# RT58X register map
Series: ARMv8-M Mainline; File version: 1.0
CPU: CM3 r0p0, little endian, MPU, no FPU, VTOR, 3 interrupt priority bits
Registers are 32-bit, read-write, reset 0x0 unless marked. A register's access mark holds for its fields unless they carry their own. Offsets are from the block's base; [hi:lo] are bit positions.

## CACHECTRL — CACHECTRL Register block
Base 0xA0200000
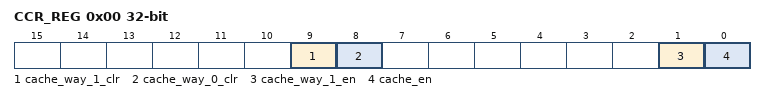
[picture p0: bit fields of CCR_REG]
0x00 CCR_REG — ccr
  [9] cache_way_1_clr wo — clear way 1 cache
    0=B_9 (clear way 1 cache)
  [8] cache_way_0_clr wo — clear way 0 cache
    0=B_8 (clear way 0 cache)
  [1] cache_way_1_en — 0: Cache 1 way (way 1 disable) 1: Cache 2 way (way 1 enable)
    0=B_1 (0: Cache 1 way (way 1 disable) 1: Cache 2 way (way 1 enable))
  [0] cache_en — 0: Cache Disable 1: Cache Enable
    0=B_0 (0: Cache Disable 1: Cache Enable)

## UART1 — UART1 Register block
Base 0xA0500000
0x00 UART1_THR_RBR_REG — uart1 thr rbr
  [7:0] THR_RBR — For write, data to be transmitted. For read, received data.
    0=B_0_to_7 (For write, data to be transmitted. For read, received data.)
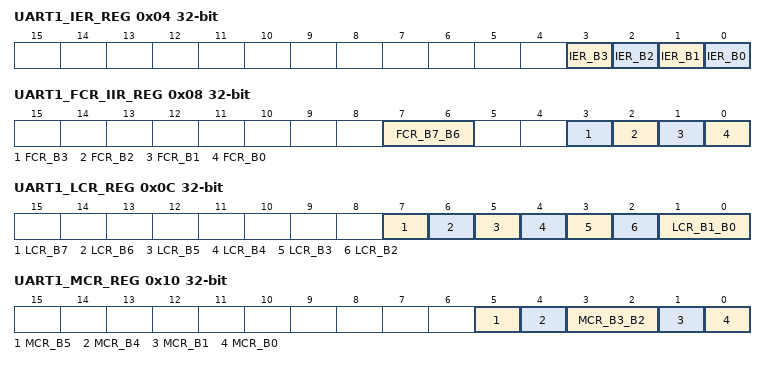
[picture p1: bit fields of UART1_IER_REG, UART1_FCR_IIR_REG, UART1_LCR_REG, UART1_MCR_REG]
0x04 UART1_IER_REG — uart1 ier
  [3] IER_B3 — Enable MODEM Status Interrupt.
    0=B_3 (Enable MODEM Status Interrupt.)
  [2] IER_B2 — Enable Receiver Line Status Interrupt.
    0=B_2 (Enable Receiver Line Status Interrupt.)
  [1] IER_B1 — Enable Transmitter Holding Register Interrupt.
    0=B_1 (Enable Transmitter Holding Register Interrupt.)
  [0] IER_B0 — Enable Received Data Available Interrupt.
    0=B_0 (Enable Received Data Available Interrupt.)
0x08 UART1_FCR_IIR_REG — uart1 fcr iir
  [7:6] FCR_B7_B6 — Receiver Trigger Level.
    0=B_6_to_7 (Receiver Trigger Level.)
  [3] FCR_B3 — DMA Mode Select. Only support 16550 Mode 1.
    0=B_3 (DMA Mode Select. Only support 16550 Mode 1.)
  [2] FCR_B2 — Transmit FIFO reset (self-clearing).
    0=B_2 (Transmit FIFO reset (self-clearing).)
  [1] FCR_B1 — Receive FIFO reset (self-clearing).
    0=B_1 (Receive FIFO reset (self-clearing).)
  [0] FCR_B0 — FIFO Enable.
    0=B_0 (FIFO Enable.)
0x0C UART1_LCR_REG — uart1 lcr
  [7] LCR_B7 — Divisor Latch Access (DLAB).
    0=B_7 (Divisor Latch Access (DLAB).)
  [6] LCR_B6 — Set Break.
    0=B_6 (Set Break.)
  [5] LCR_B5 — Stick Parity.
    0=B_5 (Stick Parity.)
  [4] LCR_B4 — Even Parity Select.
    0=B_4 (Even Parity Select.)
  [3] LCR_B3 — Parity Enable.
    0=B_3 (Parity Enable.)
  [2] LCR_B2 — Number of Stop Bits.
    0=B_2 (Number of Stop Bits.)
  [1:0] LCR_B1_B0 — Word Length Select. 0: 5-bit data 1: 6-bit data 2: 7-bit data 3: 8-bit data
    0=B_0_to_1 (Word Length Select. 0: 5-bit data 1: 6-bit data 2: 7-bit data 3: 8-bit data)
0x10 UART1_MCR_REG — uart1 mcr
  [5] MCR_B5
    0=B_5 (mcr b5)
  [4] MCR_B4 — Loopback mode select.
    0=B_4 (Loopback mode select.)
  [3:2] MCR_B3_B2 — Auxiliary user designated output.
    0=B_2_to_3 (Auxiliary user designated output.)
  [1] MCR_B1 — Request to Send (RTS).
    0=B_1 (Request to Send (RTS).)
  [0] MCR_B0 — Data Terminal Ready (DTR).
    0=B_0 (Data Terminal Ready (DTR).)
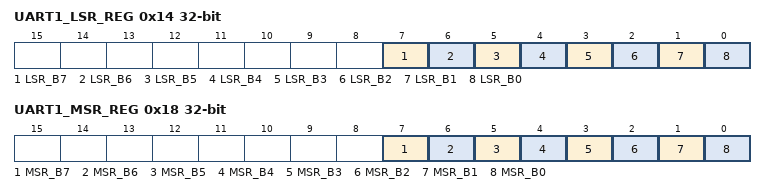
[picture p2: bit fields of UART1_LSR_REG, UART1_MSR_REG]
0x14 UART1_LSR_REG ro — uart1 lsr
  [7] LSR_B7
    0=B_7 (lsr b7)
  [6] LSR_B6 — Error in Receiver FIFO.
    0=B_6 (Error in Receiver FIFO.)
  [5] LSR_B5 — Transmitter Empty.
    0=B_5 (Transmitter Empty.)
  [4] LSR_B4 — Transmitter Holding Register Empty.
    0=B_4 (Transmitter Holding Register Empty.)
  [3] LSR_B3 — Break Interrupt.
    0=B_3 (Break Interrupt.)
  [2] LSR_B2 — Framing Error.
    0=B_2 (Framing Error.)
  [1] LSR_B1 — Parity Error.
    0=B_1 (Parity Error.)
  [0] LSR_B0 — Overrun Error.
    0=B_0 (Overrun Error.)
0x18 UART1_MSR_REG ro — uart1 msr
  [7] MSR_B7
    0=B_7 (msr b7)
  [6] MSR_B6 — Data Carrier Detect (DCD).
    0=B_6 (Data Carrier Detect (DCD).)
  [5] MSR_B5 — Ring Indicator (RI).
    0=B_5 (Ring Indicator (RI).)
  [4] MSR_B4 — Data Set Ready (DSR).
    0=B_4 (Data Set Ready (DSR).)
  [3] MSR_B3 — Clear To Send (CTS).
    0=B_3 (Clear To Send (CTS).)
  [2] MSR_B2 — Delta Data Carrier Detect (DDCD).
    0=B_2 (Delta Data Carrier Detect (DDCD).)
  [1] MSR_B1 — Trailing Edge Ring Indicator (TERI).
    0=B_1 (Trailing Edge Ring Indicator (TERI).)
  [0] MSR_B0 — Delta Data Set Ready (DDSR).
    0=B_0 (Delta Data Set Ready (DDSR).)
0x1C UART1_SCR_REG — uart1 scr
  [7:0] SCR_B7_B0
    0=B_0_to_7 (scr b7 b0)
